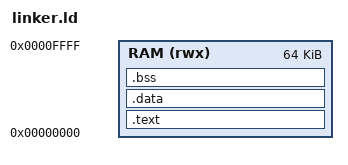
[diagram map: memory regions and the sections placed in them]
ENTRY(_start)

MEMORY
{
    RAM (rwx) : ORIGIN = 0x00000000, LENGTH = 64K
}

SECTIONS
{
    .text : {
        *(.text.start)
        *(.text*)
        *(.rodata*)
    } > RAM

    .data : {
        _data_start = .;
        *(.data*)
        _data_end = .;
    } > RAM

    .bss : {
        _bss_start = .;
        *(.bss*)
        *(COMMON)
        _bss_end = .;
    } > RAM

    /* Place stack just below 64 KB */
    _stack_top = ORIGIN(RAM) + LENGTH(RAM);
}
